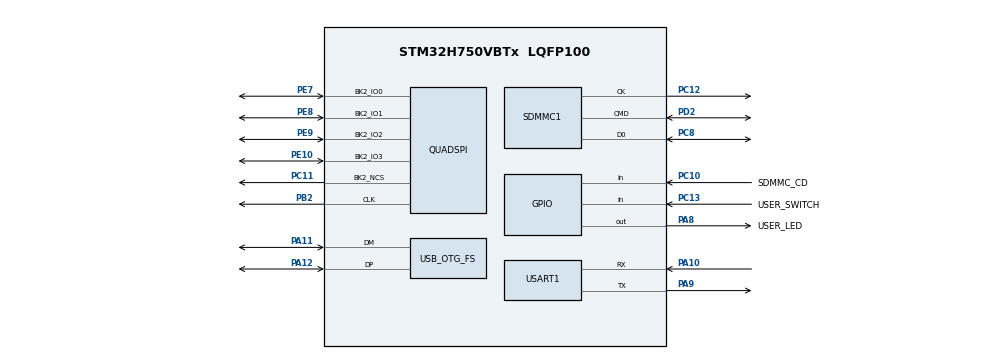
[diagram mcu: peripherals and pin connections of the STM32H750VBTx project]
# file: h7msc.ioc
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Mcu.Family=STM32H7
USB_DEVICE.CLASS_NAME_FS=MSC
RCC.CortexFreq_Value=480000000
PC10.GPIO_PuPd=GPIO_PULLUP
FATFS._USE_LFN=3
QUADSPI.ClockPrescaler=0
FATFS0.BSP.api=Unknown
RCC.HPRE=RCC_HCLK_DIV2
VP_FATFS_VS_SDIO.Mode=SDIO
PH0-OSC_IN\ (PH0).Signal=RCC_OSC_IN
PC12.Signal=SDMMC1_CK
PC10.Signal=GPIO_Input
PC15-OSC32_OUT\ (OSC32_OUT).Mode=LSE-External-Oscillator
PB2.GPIO_Speed=GPIO_SPEED_FREQ_VERY_HIGH
VP_RTC_VS_RTC_Activate.Mode=RTC_Enabled
PA11.Mode=Device_Only
PE9.GPIO_Speed=GPIO_SPEED_FREQ_VERY_HIGH
PC13.GPIO_Label=USER_SWITCH
RCC.SYSCLKSource=RCC_SYSCLKSOURCE_PLLCLK
ProjectManager.StackSize=0x400
PA14\ (JTCK/SWCLK).Signal=DEBUG_JTCK-SWCLK
PA12.Signal=USB_OTG_FS_DP
USB_DEVICE.USBD_DEBUG_LEVEL-MSC_FS=0
RCC.HCLKFreq_Value=240000000
QUADSPI.FlashSize=23
FATFS._LFN_UNICODE=0
FATFS0.BSP.ip=GPIO
PH1-OSC_OUT\ (PH1).Mode=HSE-External-Oscillator
RCC.HSE_VALUE=8000000
PB2.Signal=QUADSPI_CLK
FATFS0.BSP.i2caddr=0
RCC.DIVM2=4
RCC.DIVM1=4
PE9.Signal=QUADSPI_BK2_IO2
PC11.GPIO_Speed=GPIO_SPEED_FREQ_VERY_HIGH
PA8.Signal=GPIO_Output
PA14\ (JTCK/SWCLK).Mode=Serial_Wire
PE10.GPIO_Speed=GPIO_SPEED_FREQ_VERY_HIGH
PE10.Signal=QUADSPI_BK2_IO3
RCC.APB3Freq_Value=120000000
Mcu.Package=LQFP100
RCC.D1PPRE=RCC_APB3_DIV2
FATFS0.BSP.solution=PC10
NVIC.OTG_FS_IRQn=true\:0\:0\:false\:false\:true\:false\:true
PA10.Signal=USART1_RX
VP_RTC_VS_RTC_Calendar.Mode=RTC_Calendar
USB_OTG_FS.VirtualMode=Device_Only
PE9.Mode=Single Bank 2
PC11.Mode=Single Bank 2
PC14-OSC32_IN\ (OSC32_IN).Mode=LSE-External-Oscillator
PE8.GPIO_Speed=GPIO_SPEED_FREQ_VERY_HIGH
RCC.APB4Freq_Value=120000000
VP_USB_DEVICE_VS_USB_DEVICE_MSC_FS.Mode=MSC_FS
PC12.GPIO_PuPd=GPIO_PULLUP
PE7.Signal=QUADSPI_BK2_IO0
PH0-OSC_IN\ (PH0).Mode=HSE-External-Oscillator
QUADSPI.ChipSelectHighTime=QSPI_CS_HIGH_TIME_3_CYCLE
FATFS0.BSP.STBoard=false
USB_DEVICE.VirtualMode-MSC_FS=Msc
USB_DEVICE.PID_MSC_FS=0x572a
CORTEX_M7.CPU_ICache=Enabled
RCC.DIVQ1=20
PA13\ (JTMS/SWDIO).Mode=Serial_Wire
PC10.GPIO_Label=SDMMC_CD
PA10.Mode=Asynchronous
PD2.GPIO_PuPd=GPIO_PULLUP
USB_DEVICE.VirtualModeFS=Msc_FS
PC11.Signal=QUADSPI_BK2_NCS
PC13.Signal=GPIO_Input
FATFS0.BSP.mode=Input
PC8.Signal=SDMMC1_D0
PE10.Mode=Single Bank 2
RCC.D2PPRE2=RCC_APB2_DIV2
RCC.D2PPRE1=RCC_APB1_DIV2
USART1.FIFOMode=FIFOMODE_ENABLE
PH1-OSC_OUT\ (PH1).Signal=RCC_OSC_OUT
FATFS0.BSP.instance=PC10
PE8.Mode=Single Bank 2
USART1.VirtualMode-Asynchronous=VM_ASYNC
PA9.Mode=Asynchronous
PA8.GPIO_Label=USER_LED
ProjectManager.TargetToolchain=Makefile
PC15-OSC32_OUT\ (OSC32_OUT).Signal=RCC_OSC32_OUT
PA9.Signal=USART1_TX
RCC.DIVN2=110
RCC.DIVN1=480
RCC.USBFreq_Value=48000000
PD2.Mode=SD_1_bit
FATFS.BSP.number=1
PC12.Mode=SD_1_bit
board=custom
PE7.GPIO_Speed=GPIO_SPEED_FREQ_VERY_HIGH
RCC.APB2Freq_Value=120000000
PE8.Signal=QUADSPI_BK2_IO1
RCC.ADCFreq_Value=110000000
Mcu.Name=STM32H750VBTx
PC8.Mode=SD_1_bit
PC8.GPIO_PuPd=GPIO_PULLUP
RCC.SYSCLKFreq_VALUE=480000000
PE7.Mode=Single Bank 2
PA12.Mode=Device_Only
PC14-OSC32_IN\ (OSC32_IN).Signal=RCC_OSC32_IN
PB2.Mode=Single Bank 2
RCC.QSPICLockSelection=RCC_QSPICLKSOURCE_PLL2
PA11.Signal=USB_OTG_FS_DM
ProjectManager.HeapSize=0x200
NVIC.PriorityGroup=NVIC_PRIORITYGROUP_4
RCC.D3PPRE=RCC_APB4_DIV2
CORTEX_M7.CPU_DCache=Enabled
PD2.Signal=SDMMC1_CMD
RCC.APB1Freq_Value=120000000
FATFS0.BSP.name=Detect_SDIO
PA13\ (JTMS/SWDIO).Signal=DEBUG_JTMS-SWDIO

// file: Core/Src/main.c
/* USER CODE BEGIN Header */
/**
  ******************************************************************************
  * @file           : main.c
  * @brief          : Main program body
  ******************************************************************************
  * @attention
  *
  * <h2><center>&copy; Copyright (c) 2020 STMicroelectronics.
  * All rights reserved.</center></h2>
  *
  * This software component is licensed by ST under Ultimate Liberty license
  * SLA0044, the "License"; You may not use this file except in compliance with
  * the License. You may obtain a copy of the License at:
  *                             www.st.com/SLA0044
  *
  ******************************************************************************
  */
/* USER CODE END Header */
#include "main.h"
#include "fatfs.h"
#include "usb_device.h"

/* USER CODE BEGIN Includes */
#include "user.h"
#include "qspi.h"
/* USER CODE END Includes */

QSPI_HandleTypeDef hqspi;

SD_HandleTypeDef hsd1;

void SystemClock_Config(void);
static void MX_GPIO_Init(void);
static void MX_USART1_UART_Init(void);
void MX_QUADSPI_Init(void);
static void MX_RTC_Init(void);
static void MX_SDMMC1_SD_Init(void);

int main(void)
{

  /* Enable I-Cache---------------------------------------------------------*/
  SCB_EnableICache();

  /* Enable D-Cache---------------------------------------------------------*/
  SCB_EnableDCache();

  /* MCU Configuration--------------------------------------------------------*/

  /* Reset of all peripherals, Initializes the Flash interface and the Systick. */
  HAL_Init();

  /* Configure the system clock */
  SystemClock_Config();

  /* Initialize all configured peripherals */
  MX_GPIO_Init();
  MX_USB_DEVICE_Init();
  MX_USART1_UART_Init();
  MX_QUADSPI_Init();
  MX_RTC_Init();
  MX_SDMMC1_SD_Init();
  MX_FATFS_Init();
  /* USER CODE BEGIN 2 */
  if (LL_GPIO_IsInputPinSet(USER_SWITCH_GPIO_Port, USER_SWITCH_Pin)) {
    extern void boot_process(void);
    boot_process();
  }

  USER_setup();
  /* USER CODE END 2 */

  /* Infinite loop */
  while (1)
  {

    /* USER CODE BEGIN 3 */
    USER_loop();
  }
  /* USER CODE END 3 */
}

void SystemClock_Config(void)
{
  LL_FLASH_SetLatency(LL_FLASH_LATENCY_4);
  while(LL_FLASH_GetLatency()!= LL_FLASH_LATENCY_4)
  {
  }
  LL_PWR_ConfigSupply(LL_PWR_LDO_SUPPLY);
  LL_PWR_SetRegulVoltageScaling(LL_PWR_REGU_VOLTAGE_SCALE0);
  LL_RCC_HSE_Enable();

   /* Wait till HSE is ready */
  while(LL_RCC_HSE_IsReady() != 1)
  {

  }
  LL_RCC_LSI_Enable();

   /* Wait till LSI is ready */
  while(LL_RCC_LSI_IsReady() != 1)
  {

  }
  LL_PWR_EnableBkUpAccess();
  LL_RCC_ForceBackupDomainReset();
  LL_RCC_ReleaseBackupDomainReset();
  LL_RCC_EnableRTC();
  LL_RCC_PLL_SetSource(LL_RCC_PLLSOURCE_HSE);
  LL_RCC_PLL1P_Enable();
  LL_RCC_PLL1Q_Enable();
  LL_RCC_PLL1R_Enable();
  LL_RCC_PLL1_SetVCOInputRange(LL_RCC_PLLINPUTRANGE_2_4);
  LL_RCC_PLL1_SetVCOOutputRange(LL_RCC_PLLVCORANGE_WIDE);
  LL_RCC_PLL1_SetM(4);
  LL_RCC_PLL1_SetN(480);
  LL_RCC_PLL1_SetP(2);
  LL_RCC_PLL1_SetQ(20);
  LL_RCC_PLL1_SetR(2);
  LL_RCC_PLL1_Enable();

   /* Wait till PLL is ready */
  while(LL_RCC_PLL1_IsReady() != 1)
  {
  }

  LL_RCC_PLL2R_Enable();
  LL_RCC_PLL2_SetVCOInputRange(LL_RCC_PLLINPUTRANGE_2_4);
  LL_RCC_PLL2_SetVCOOutputRange(LL_RCC_PLLVCORANGE_WIDE);
  LL_RCC_PLL2_SetM(4);
  LL_RCC_PLL2_SetN(110);
  LL_RCC_PLL2_SetP(2);
  LL_RCC_PLL2_SetQ(2);
  LL_RCC_PLL2_SetR(2);
  LL_RCC_PLL2_Enable();

   /* Wait till PLL is ready */
  while(LL_RCC_PLL2_IsReady() != 1)
  {
  }

   /* Intermediate AHB prescaler 2 when target frequency clock is higher than 80 MHz */
   LL_RCC_SetAHBPrescaler(LL_RCC_AHB_DIV_2);

  LL_RCC_SetSysClkSource(LL_RCC_SYS_CLKSOURCE_PLL1);
  LL_RCC_SetSysPrescaler(LL_RCC_SYSCLK_DIV_1);
  LL_RCC_SetAHBPrescaler(LL_RCC_AHB_DIV_2);
  LL_RCC_SetAPB1Prescaler(LL_RCC_APB1_DIV_2);
  LL_RCC_SetAPB2Prescaler(LL_RCC_APB2_DIV_2);
  LL_RCC_SetAPB3Prescaler(LL_RCC_APB3_DIV_2);
  LL_RCC_SetAPB4Prescaler(LL_RCC_APB4_DIV_2);
  LL_SetSystemCoreClock(480000000);

   /* Update the time base */
  if (HAL_InitTick (TICK_INT_PRIORITY) != HAL_OK)
  {
    Error_Handler();
  }
  LL_RCC_SetRTCClockSource(LL_RCC_RTC_CLKSOURCE_LSI);
  LL_RCC_SetQSPIClockSource(LL_RCC_QSPI_CLKSOURCE_PLL2R);
  LL_RCC_SetSDMMCClockSource(LL_RCC_SDMMC_CLKSOURCE_PLL1Q);
  LL_RCC_SetUSARTClockSource(LL_RCC_USART16_CLKSOURCE_PCLK2);
  LL_RCC_SetUSBClockSource(LL_RCC_USB_CLKSOURCE_PLL1Q);
}

void MX_QUADSPI_Init(void)
{

  /* QUADSPI parameter configuration*/
  hqspi.Instance = QUADSPI;
  hqspi.Init.ClockPrescaler = 0;
  hqspi.Init.FifoThreshold = 1;
  hqspi.Init.SampleShifting = QSPI_SAMPLE_SHIFTING_NONE;
  hqspi.Init.FlashSize = 23;
  hqspi.Init.ChipSelectHighTime = QSPI_CS_HIGH_TIME_3_CYCLE;
  hqspi.Init.ClockMode = QSPI_CLOCK_MODE_0;
  hqspi.Init.FlashID = QSPI_FLASH_ID_2;
  hqspi.Init.DualFlash = QSPI_DUALFLASH_DISABLE;
  if (HAL_QSPI_Init(&hqspi) != HAL_OK)
  {
    Error_Handler();
  }
  /* USER CODE BEGIN QUADSPI_Init 2 */
  if (QSPI_ResetMemory(&hqspi) != QSPI_OK) {
    Error_Handler();
  }
  /* USER CODE END QUADSPI_Init 2 */

}

static void MX_RTC_Init(void)
{

  LL_RTC_InitTypeDef RTC_InitStruct = {0};
  LL_RTC_TimeTypeDef RTC_TimeStruct = {0};
  LL_RTC_DateTypeDef RTC_DateStruct = {0};

  /* Peripheral clock enable */
  LL_RCC_EnableRTC();

  /** Initialize RTC and set the Time and Date
  */
  RTC_InitStruct.HourFormat = LL_RTC_HOURFORMAT_24HOUR;
  RTC_InitStruct.AsynchPrescaler = 127;
  RTC_InitStruct.SynchPrescaler = 255;
  LL_RTC_Init(RTC, &RTC_InitStruct);
  /** Initialize RTC and set the Time and Date
  */
  RTC_TimeStruct.Hours = 0x0;
  RTC_TimeStruct.Minutes = 0x0;
  RTC_TimeStruct.Seconds = 0x0;

  LL_RTC_TIME_Init(RTC, LL_RTC_FORMAT_BCD, &RTC_TimeStruct);
  RTC_DateStruct.WeekDay = LL_RTC_WEEKDAY_MONDAY;
  RTC_DateStruct.Month = LL_RTC_MONTH_JANUARY;
  RTC_DateStruct.Day = 0x1;
  RTC_DateStruct.Year = 0x0;

  LL_RTC_DATE_Init(RTC, LL_RTC_FORMAT_BCD, &RTC_DateStruct);

}

static void MX_SDMMC1_SD_Init(void)
{

  hsd1.Instance = SDMMC1;
  hsd1.Init.ClockEdge = SDMMC_CLOCK_EDGE_RISING;
  hsd1.Init.ClockPowerSave = SDMMC_CLOCK_POWER_SAVE_DISABLE;
  hsd1.Init.BusWide = SDMMC_BUS_WIDE_1B;
  hsd1.Init.HardwareFlowControl = SDMMC_HARDWARE_FLOW_CONTROL_DISABLE;
  hsd1.Init.ClockDiv = 0;
  hsd1.Init.TranceiverPresent = SDMMC_TRANSCEIVER_NOT_PRESENT;

}

static void MX_USART1_UART_Init(void)
{

  LL_USART_InitTypeDef USART_InitStruct = {0};

  LL_GPIO_InitTypeDef GPIO_InitStruct = {0};

  /* Peripheral clock enable */
  LL_APB2_GRP1_EnableClock(LL_APB2_GRP1_PERIPH_USART1);

  LL_AHB4_GRP1_EnableClock(LL_AHB4_GRP1_PERIPH_GPIOA);
  /**USART1 GPIO Configuration
  PA9   ------> USART1_TX
  PA10   ------> USART1_RX
  */
  GPIO_InitStruct.Pin = LL_GPIO_PIN_9|LL_GPIO_PIN_10;
  GPIO_InitStruct.Mode = LL_GPIO_MODE_ALTERNATE;
  GPIO_InitStruct.Speed = LL_GPIO_SPEED_FREQ_LOW;
  GPIO_InitStruct.OutputType = LL_GPIO_OUTPUT_PUSHPULL;
  GPIO_InitStruct.Pull = LL_GPIO_PULL_NO;
  GPIO_InitStruct.Alternate = LL_GPIO_AF_7;
  LL_GPIO_Init(GPIOA, &GPIO_InitStruct);

  USART_InitStruct.PrescalerValue = LL_USART_PRESCALER_DIV1;
  USART_InitStruct.BaudRate = 115200;
  USART_InitStruct.DataWidth = LL_USART_DATAWIDTH_8B;
  USART_InitStruct.StopBits = LL_USART_STOPBITS_1;
  USART_InitStruct.Parity = LL_USART_PARITY_NONE;
  USART_InitStruct.TransferDirection = LL_USART_DIRECTION_TX_RX;
  USART_InitStruct.HardwareFlowControl = LL_USART_HWCONTROL_NONE;
  USART_InitStruct.OverSampling = LL_USART_OVERSAMPLING_16;
  LL_USART_Init(USART1, &USART_InitStruct);
  LL_USART_SetTXFIFOThreshold(USART1, LL_USART_FIFOTHRESHOLD_1_8);
  LL_USART_SetRXFIFOThreshold(USART1, LL_USART_FIFOTHRESHOLD_1_8);
  LL_USART_EnableFIFO(USART1);
  LL_USART_ConfigAsyncMode(USART1);

  LL_USART_Enable(USART1);

  /* Polling USART1 initialisation */
  while((!(LL_USART_IsActiveFlag_TEACK(USART1))) || (!(LL_USART_IsActiveFlag_REACK(USART1))))
  {
  }

}

static void MX_GPIO_Init(void)
{
  LL_GPIO_InitTypeDef GPIO_InitStruct = {0};

  /* GPIO Ports Clock Enable */
  LL_AHB4_GRP1_EnableClock(LL_AHB4_GRP1_PERIPH_GPIOC);
  LL_AHB4_GRP1_EnableClock(LL_AHB4_GRP1_PERIPH_GPIOH);
  LL_AHB4_GRP1_EnableClock(LL_AHB4_GRP1_PERIPH_GPIOB);
  LL_AHB4_GRP1_EnableClock(LL_AHB4_GRP1_PERIPH_GPIOE);
  LL_AHB4_GRP1_EnableClock(LL_AHB4_GRP1_PERIPH_GPIOA);
  LL_AHB4_GRP1_EnableClock(LL_AHB4_GRP1_PERIPH_GPIOD);

  /**/
  LL_GPIO_ResetOutputPin(USER_LED_GPIO_Port, USER_LED_Pin);

  /**/
  GPIO_InitStruct.Pin = USER_SWITCH_Pin;
  GPIO_InitStruct.Mode = LL_GPIO_MODE_INPUT;
  GPIO_InitStruct.Pull = LL_GPIO_PULL_NO;
  LL_GPIO_Init(USER_SWITCH_GPIO_Port, &GPIO_InitStruct);

  /**/
  GPIO_InitStruct.Pin = USER_LED_Pin;
  GPIO_InitStruct.Mode = LL_GPIO_MODE_OUTPUT;
  GPIO_InitStruct.Speed = LL_GPIO_SPEED_FREQ_LOW;
  GPIO_InitStruct.OutputType = LL_GPIO_OUTPUT_PUSHPULL;
  GPIO_InitStruct.Pull = LL_GPIO_PULL_NO;
  LL_GPIO_Init(USER_LED_GPIO_Port, &GPIO_InitStruct);

  /**/
  GPIO_InitStruct.Pin = SDMMC_CD_Pin;
  GPIO_InitStruct.Mode = LL_GPIO_MODE_INPUT;
  GPIO_InitStruct.Pull = LL_GPIO_PULL_UP;
  LL_GPIO_Init(SDMMC_CD_GPIO_Port, &GPIO_InitStruct);

}

void Error_Handler(void)
{
  /* USER CODE BEGIN Error_Handler_Debug */
  /* User can add his own implementation to report the HAL error return state */
  __BKPT(0);
  while (1) {}
  /* USER CODE END Error_Handler_Debug */
}

/************************ (C) COPYRIGHT STMicroelectronics *****END OF FILE****/
